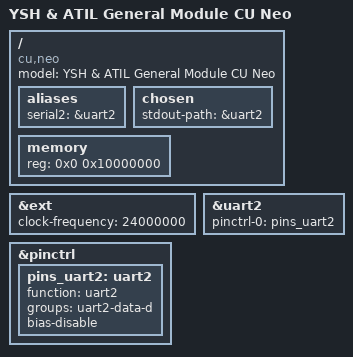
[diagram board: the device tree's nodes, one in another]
// SPDX-License-Identifier: GPL-2.0
/dts-v1/;

#include "x1000.dtsi"
#include <dt-bindings/gpio/gpio.h>

/ {
	model = "YSH & ATIL General Module CU Neo";
	compatible = "cu,neo", "ingenic,x1000";

	aliases {
		serial2 = &uart2;
	};

	chosen {
		stdout-path = &uart2;
	};

	memory {
		device_type = "memory";
		reg = <0x0 0x10000000>;
	};
};

&ext {
	clock-frequency = <24000000>;
};

&uart2 {
	status = "okay";

	pinctrl-names = "default";
	pinctrl-0 = <&pins_uart2>;
};

&pinctrl {
	pins_uart2: uart2 {
		function = "uart2";
		groups = "uart2-data-d";
		bias-disable;
	};
};
